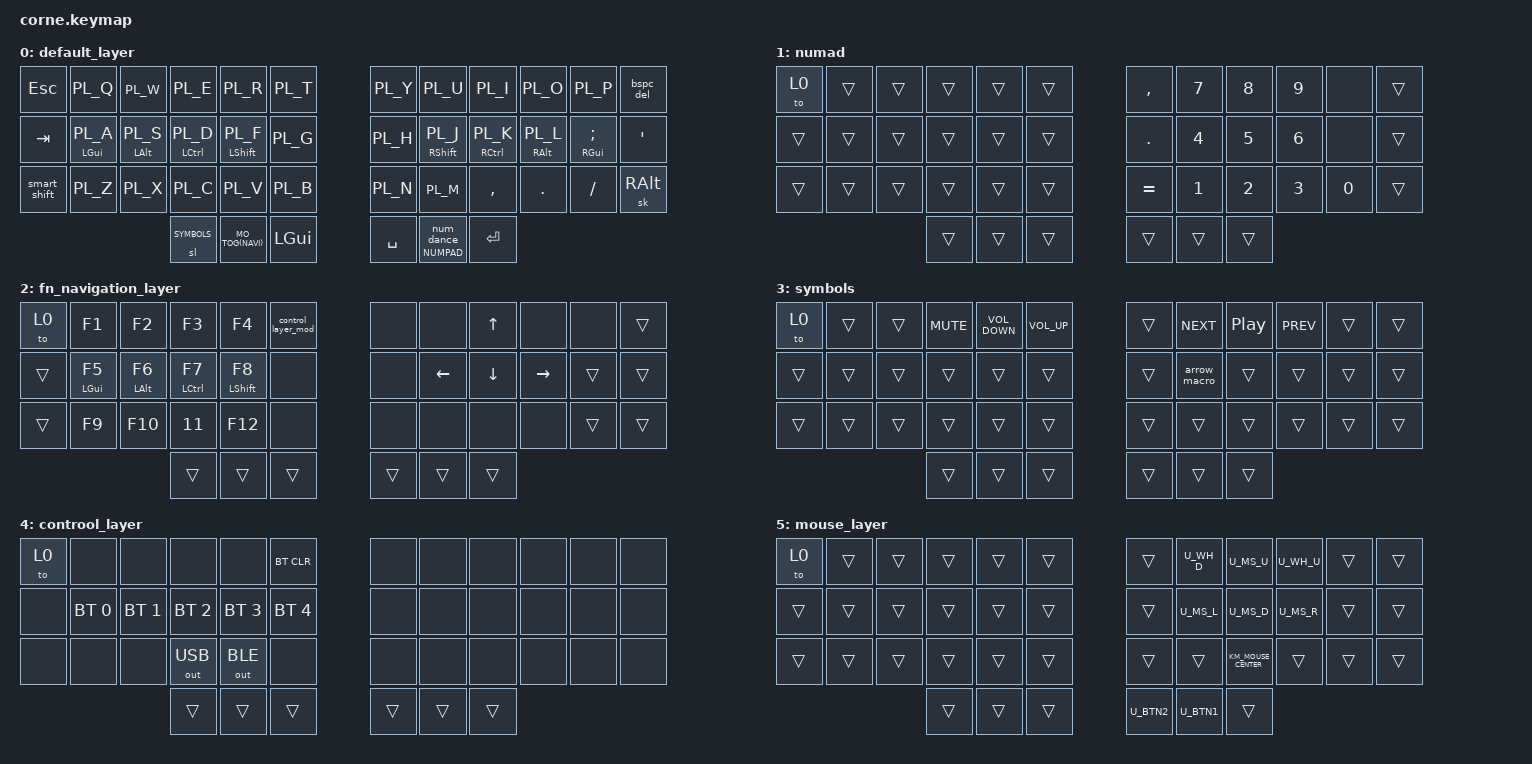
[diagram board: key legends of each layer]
/*
 * Copyright (c) 2020 The ZMK Contributors
 *
 * SPDX-License-Identifier: MIT
 */

#include <behaviors.dtsi>
#include <dt-bindings/zmk/bt.h>
#include <dt-bindings/zmk/keys.h>
#include <dt-bindings/zmk/outputs.h>
#include "keys_pl_programmers.h"
#include "keypos_42keys.h"

#define MO_TOG(layer) &mo_tog layer layer
#define SL_TOG(layer) &sl_tog layer layer
#define SMART_NUM &smart_num NUMPAD 0

#define BASE 0
#define NUMPAD 1
#define NAVI 2
#define SYMBOLS 3
#define CONTROL 4
#define MOUSE 5

#define KEYS_L LT0 LT1 LT2 LT3 LT4 LT5 LM0 LM1 LM2 LM3 LM4 LM5 LB0 LB1 LB2 LB3 LB4 LB5  // left hand
#define KEYS_R RT0 RT1 RT2 RT3 RT4 RT5 RM0 RM1 RM2 RM3 RM4 RM5 RB0 RB1 RB2 RB3 RB4 LB5  // right hand
#define THUMBS LH2 LH1 LH0 RH0 RH1 RH2                                      // thumbs

#define XXX &none
#define ___ &trans
#define KM_MOUSE_CENTER RA(RG(S))

#define QUICK_TAP_MS 175

#include "combos.dtsi"
#include "mouse.dtsi"

&caps_word {
    /delete-property/ ignore-modifiers;
};
&num_word {  // num-word, requires PR #1451
    layers = <NUMPAD>;
    continue-list = <BSPC DEL DOT COMMA PLUS MINUS STAR FSLH EQUAL RET>;
};

/ {
    macros {
        arrow_macro: arrow_macro {
            label = "ZM_zed_em_kay";
            compatible = "zmk,behavior-macro";
            #binding-cells = <0>;
            
            wait-ms = <40>;
            tap-ms = <40>;
            bindings
                = <&kp KP_EQUAL &kp GREATER_THAN >
                ;
        };
    };

    behaviors {
        bspc_del: backspace_delete {
            compatible = "zmk,behavior-mod-morph";
            label = "BACKSPACE_DELETE";
            #binding-cells = <0>;
            bindings = <&kp BACKSPACE>, <&kp DELETE>;
            mods = <(MOD_LSFT|MOD_RSFT)>;
            keep-mods = <(MOD_RSFT)>;
        };

        td_shift: tap_dance_0 {
            compatible = "zmk,behavior-tap-dance";
            label = "shift-caps word";
            #binding-cells = <0>;
            tapping-term-ms = <400>;
            bindings = <&sk LSHFT>, <&caps_word>;
        };

        smart_shift: smart_shift {
            compatible = "zmk,behavior-mod-morph";
            label = "smart_shift";
            #binding-cells = <0>;
            bindings = <&sk LSHFT>, <&caps_word>;
            mods = <(MOD_LSFT)>;
        };

        mo_tog: behavior_mo_tog {
            compatible = "zmk,behavior-hold-tap";
            label = "mo_tog";
            #binding-cells = <2>;
            flavor = "hold-preferred";
            tapping-term-ms = <200>;
            bindings = <&mo>, <&tog>;
        };

        sl_tog: behavior_sl_tog {
            compatible = "zmk,behavior-hold-tap";
            label = "sl_tog";
            #binding-cells = <2>;
            flavor = "hold-preferred";
            tapping-term-ms = <200>;
            bindings = <&mo>, <&sl>;
        };

        control_layer_mod: control_layer_mod {
            compatible = "zmk,behavior-mod-morph";
            label = "control_layer_mod";
            #binding-cells = <0>;
            bindings = <&none>, <&tog CONTROL>;
            mods = <(MOD_LSFT)>;
        };

        // tap: left-parenthesis | shft + tap: less-than
        lpar_lt: lpar_lt {
            compatible = "zmk,behavior-mod-morph";
            label = "lpar_lt";
            #binding-cells = <0>;
            bindings = <&kp LPAR>, <&kp LT>;
            mods = <(MOD_LSFT|MOD_RSFT)>;
        };

        // tap: right-parenthesis | shft + tap: less-than
        rpar_gt: rpar_gt {
            compatible = "zmk,behavior-mod-morph";
            label = "rpar_gt";
            #binding-cells = <0>;
            bindings = <&kp RPAR>, <&kp GT>;
            mods = <(MOD_LSFT|MOD_RSFT)>;
        };
        
        hmr_lpar_lt: hmr_lpar_lt {
            compatible = "zmk,behavior-hold-tap";
            label = "hmr_lpar_lt";
            #binding-cells = <2>;
            flavor = "balanced";
            tapping-term-ms = <280>;
            quick-tap-ms = <QUICK_TAP_MS>;
            require-prior-idle-ms = <150>;
            bindings = <&kp>, <&lpar_lt>;
            hold-trigger-key-positions = <KEYS_L THUMBS>;
            hold-trigger-on-release;
        };

        hmr_rpar_gt: hmr_rpar_gt {
            compatible = "zmk,behavior-hold-tap";
            label = "hmr_rpar_gt";
            #binding-cells = <2>;
            flavor = "balanced";
            tapping-term-ms = <280>;
            quick-tap-ms = <QUICK_TAP_MS>;
            require-prior-idle-ms = <150>;
            bindings = <&kp>, <&rpar_gt>;
            hold-trigger-key-positions = <KEYS_L THUMBS>;
            hold-trigger-on-release;
        };

        hml: hml {
            compatible = "zmk,behavior-hold-tap";
            label = "hml";
            #binding-cells = <2>;
            flavor = "balanced";
            tapping-term-ms = <280>;
            quick-tap-ms = <QUICK_TAP_MS>;
            require-prior-idle-ms = <150>;
            bindings = <&kp>, <&kp>;
            hold-trigger-key-positions = <KEYS_R THUMBS>;
            hold-trigger-on-release;
        };
        hmr: hmr {
            compatible = "zmk,behavior-hold-tap";
            label = "hmr";
            #binding-cells = <2>;
            flavor = "balanced";
            tapping-term-ms = <280>;
            quick-tap-ms = <QUICK_TAP_MS>;
            require-prior-idle-ms = <150>; 
            bindings = <&kp>, <&kp>;
            hold-trigger-key-positions = <KEYS_L THUMBS>;
            hold-trigger-on-release;
        };
// CMD should work on mouse layer
        smart_mouse: smart_mouse {
            compatible = "zmk,behavior-tri-state";
            label = "smart_mouse";
            #binding-cells = <0>;
            bindings = <&tog MOUSE>, <&none>, <&tog MOUSE>;
            ignored-key-positions = <LT1 LT3 RT1 RT2 RT3 RM1 RM2 RM3 RB2 RH0 RH1>;
            ignored-layers = <MOUSE>;
        };

        smart_num: smart_num {
            compatible = "zmk,behavior-hold-tap";
            label = "smart_num";
            #binding-cells = <2>;
            flavor = "balanced";
            tapping-term-ms = <200>;
            quick-tap-ms = <QUICK_TAP_MS>;
            bindings = <&mo>, <&num_dance>;
        };
        num_dance: num_dance {
            compatible = "zmk,behavior-tap-dance";
            label = "num_dance";
            #binding-cells = <0>;
            tapping-term-ms = <200>;
            bindings = <&num_word>, <&sl NUMPAD>;  // reverse this for sticky-num on single tap
        };
    };

    keymap {
        compatible = "zmk,keymap";

        default_layer {
            bindings = <
     &kp ESC &kp PL_Q       &kp PL_W        &kp PL_E         &kp PL_R        &kp PL_T        &kp PL_Y  &kp PL_U          &kp PL_I         &kp PL_O        &kp PL_P        &bspc_del
     &kp TAB  &hml LGUI PL_A &hml LALT PL_S &hml LCTRL PL_D  &hml LSHFT PL_F &kp PL_G        &kp PL_H  &hmr RSHIFT PL_J  &hmr RCTRL PL_K  &hmr RALT PL_L  &hmr RGUI SEMI    &kp SQT
&smart_shift  &kp PL_Z       &kp PL_X       &kp PL_C         &kp PL_V        &kp PL_B        &kp PL_N  &kp PL_M          &kp COMMA        &kp DOT         &kp FSLH         &sk RALT
                                            &sl SYMBOLS      MO_TOG(NAVI)   &kp LEFT_GUI        &kp SPACE SMART_NUM   &kp RET
            >;
        };

        numad {
            bindings = <
&to 0   &trans  &trans  &trans  &trans &trans    &kp COMMA  &kp N7  &kp N8  &kp N9   &none   &trans
&trans  &trans  &trans  &trans  &trans &trans    &kp DOT    &kp N4  &kp N5  &kp N6   &none   &trans
&trans  &trans  &trans  &trans  &trans &trans    &kp EQUAL  &kp N1  &kp N2  &kp N3   &kp N0  &trans
                        &trans  &trans &trans    &trans  &trans  &trans
            >;
        };

        fn_navigation_layer {
            bindings = <
&to 0   &kp F1        &kp F2        &kp F3        &kp F4        &control_layer_mod       &none     &none    &kp UP        &none   &none   &trans
&trans  &hml LGUI F5  &hml LALT F6  &hml LCTRL F7 &hml LSHFT F8              &none       &none  &kp LEFT    &kp DOWN  &kp RIGHT   &trans  &trans
&trans  &kp F9        &kp F10       &kp 11        &kp F12                    &none       &none     &none    &none         &none   &trans  &trans
                                                       &trans      &trans   &trans      &trans    &trans    &trans
            >;
        };

        symbols {
            bindings = <
&to 0  ___   ___   &kp C_MUTE   &kp C_VOL_DOWN   &kp C_VOL_UP       ___  &kp C_NEXT        &kp C_PLAY_PAUSE  &kp C_PREV   ___   ___
___    ___   ___   ___          ___              ___                ___  &arrow_macro      ___               ___          ___   ___
___    ___   ___   ___          ___              ___                ___  ___               ___               ___          ___   ___
                   ___          ___              ___                ___  ___               ___       
            >;
        };

        controol_layer {
            bindings = <
&to 0   &none         &none         &none         &none           &bt BT_CLR       &none  &none  &none  &none  &none  &none
&none   &bt BT_SEL 0  &bt BT_SEL 1  &bt BT_SEL 2  &bt BT_SEL 3  &bt BT_SEL 4       &none  &none  &none  &none  &none  &none
&none   &none         &none         &out OUT_USB  &out OUT_BLE         &none       &none  &none  &none  &none  &none  &none
                                                        &trans &trans &trans       &trans &trans &trans
            >;
        };

        mouse_layer {
            bindings = <
&to 0  ___   ___   ___   ___   ___       ___     U_WH_D      U_MS_U             U_WH_U  ___   ___
___    ___   ___   ___   ___   ___       ___     U_MS_L      U_MS_D             U_MS_R  ___   ___
___    ___   ___   ___   ___   ___       ___     ___     &kp KM_MOUSE_CENTER    ___     ___   ___
                   ___   ___   ___       U_BTN2  U_BTN1  ___
            >;
        };

    };
};
